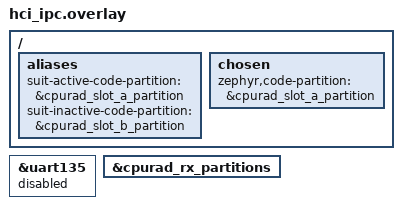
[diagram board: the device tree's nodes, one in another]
/*
 * Copyright (c) 2025 Nordic Semiconductor ASA
 *
 * SPDX-License-Identifier: LicenseRef-Nordic-5-Clause
 */

#include "nrf54h20dk_nrf54h20_memory_map.dtsi"

/* Disable logs from Radio core on UART 1 */
&uart135 {
	status = "disabled";
};

/* Enable partitions, belonging to the radio domain. */
&cpurad_rx_partitions {
	status = "okay";
};

/ {
	aliases {
		suit-active-code-partition = &cpurad_slot_a_partition;
		suit-inactive-code-partition = &cpurad_slot_b_partition;
	};

	chosen {
		zephyr,code-partition = &cpurad_slot_a_partition;
	};
};
